# MCU_NAVSS0_PSILCFG_0_UDMASS_PSILSS_CFG0_PROXY register map
Vendor: Texas Instruments
Peripheral module from a debugger description file (folder J721S2).
Registers are 32-bit, read-write, reset 0x0 unless marked. A register's access mark holds for its fields unless they carry their own. Offsets are as the file gives them; lines under a group give offsets from that group; [hi:lo] are bit positions; {n}, {i} and the like mark numbered series; 'fields as' and 'values as' point back to an identical list; <NAME> marks a mode.

## MCU_NAVSS0_PSILCFG_0_UDMASS_PSILSS_CFG0_PROXY
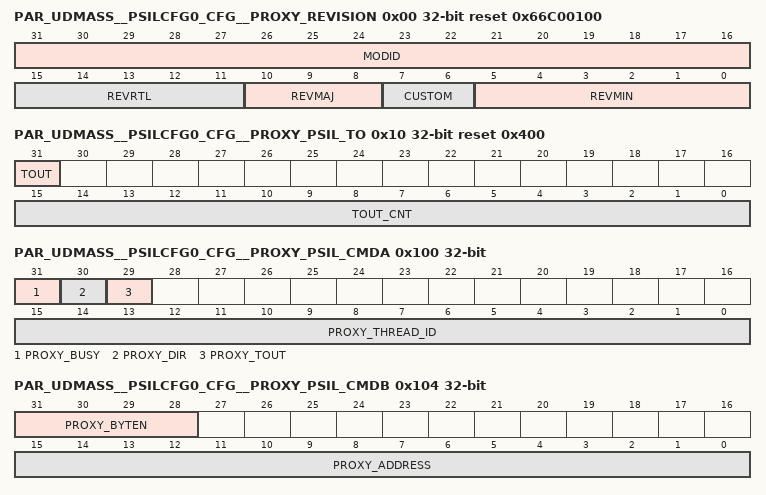
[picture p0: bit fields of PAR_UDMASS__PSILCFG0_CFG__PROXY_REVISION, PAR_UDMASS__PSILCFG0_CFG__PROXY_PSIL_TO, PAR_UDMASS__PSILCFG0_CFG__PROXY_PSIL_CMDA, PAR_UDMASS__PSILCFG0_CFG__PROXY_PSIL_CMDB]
0x00 PAR_UDMASS__PSILCFG0_CFG__PROXY_REVISION ro reset 0x66C00100 — The Revision Register contains the major and minor revisions for the module.
  [31:16] MODID — Module ID field
  [15:11] REVRTL — RTL revision. Will vary depending on release.
  [10:8] REVMAJ — Major revision
  [7:6] CUSTOM
  [5:0] REVMIN — Minor revision
0x10 PAR_UDMASS__PSILCFG0_CFG__PROXY_PSIL_TO reset 0x400 — The PSI-L proxy timeout register controls the timeout watchdog and reports timeout occurrances on PSI-L configuration transactions issued by the built in PSI-L proxy.
  [31] TOUT — Timeout occurred. When set indicates that a timeout has occurred on a config access. Once set, this bit is persistent until manually cleared
  [15:0] TOUT_CNT — Timeout period. Specifies how many cycles to wait before closing up a conifiguration read or write transaction and asserting the tout bit
0x100 PAR_UDMASS__PSILCFG0_CFG__PROXY_PSIL_CMDA — The Command Register A contains the busy indicator, direction, and thread number for the configuration transaction.
  [31] PROXY_BUSY — Indication that a configuration read or write is in progress
  [30] PROXY_DIR — Direction of configuration transaction
  [29] PROXY_TOUT — Indication that a timeout occurred. This bit should be written to 0 on each new transaction.
  [15:0] PROXY_THREAD_ID — Thread ID to which configuration read or write is being sent
0x104 PAR_UDMASS__PSILCFG0_CFG__PROXY_PSIL_CMDB — The Command Register B contains the byte enables and word address for the configuration transaction.
  [31:28] PROXY_BYTEN — Byte enables to use for configuration read or write
  [15:0] PROXY_ADDRESS — Word (32-bit) address within thread configuration space for transaction
0x108 PAR_UDMASS__PSILCFG0_CFG__PROXY_PSIL_WDATA — The Write Data Register contains the data which is to be written during the configuration transaction.
  [31:0] PROXY_WDATA — Configuration data word to be written
0x140 PAR_UDMASS__PSILCFG0_CFG__PROXY_PSIL_RDATA — The Read Data Register contains the data which which was read back during the configuration transaction.
  [31:0] PROXY_RDATA — Configuration data word that was read
